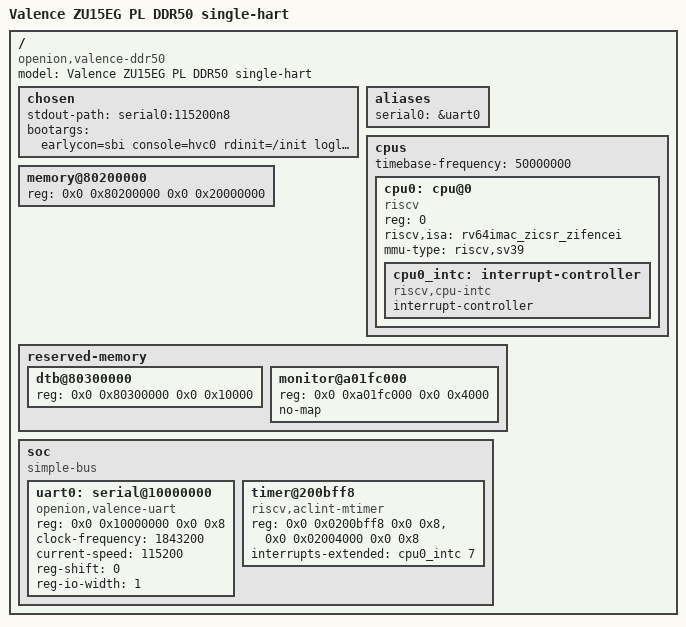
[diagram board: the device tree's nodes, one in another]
/dts-v1/;

/ {
    #address-cells = <2>;
    #size-cells = <2>;
    compatible = "openion,valence-ddr50";
    model = "Valence ZU15EG PL DDR50 single-hart";

    chosen {
        stdout-path = "serial0:115200n8";
        bootargs = "earlycon=sbi console=hvc0 rdinit=/init loglevel=7";
    };
    aliases { serial0 = &uart0; };
    cpus {
        #address-cells = <1>;
        #size-cells = <0>;
        timebase-frequency = <50000000>;
        cpu0: cpu@0 {
            device_type = "cpu";
            reg = <0>;
            compatible = "riscv";
            riscv,isa = "rv64imac_zicsr_zifencei";
            mmu-type = "riscv,sv39";
            status = "okay";
            cpu0_intc: interrupt-controller {
                compatible = "riscv,cpu-intc";
                interrupt-controller;
                #address-cells = <0>;
                #interrupt-cells = <1>;
            };
        };
    };
    memory@80200000 {
        device_type = "memory";
        reg = <0x0 0x80200000 0x0 0x20000000>;
    };
    reserved-memory {
        #address-cells = <2>;
        #size-cells = <2>;
        ranges;
        /* OpenSBI adds its own resident firmware reservation at runtime. */
        dtb@80300000 { reg = <0x0 0x80300000 0x0 0x10000>; };
        monitor@a01fc000 {
            reg = <0x0 0xa01fc000 0x0 0x4000>;
            no-map;
        };
    };
    soc {
        compatible = "simple-bus";
        #address-cells = <2>;
        #size-cells = <2>;
        ranges;
        /* No standard CPU-writable IMSIC aperture: do NOT describe AIA here.
         * Linux uses SBI DBCN/hvc polling. UART IRQ3 is not used in this image. */
        uart0: serial@10000000 {
            compatible = "openion,valence-uart", "ns16550a";
            reg = <0x0 0x10000000 0x0 0x8>;
            clock-frequency = <1843200>;
            current-speed = <115200>;
            reg-shift = <0>;
            reg-io-width = <1>;
            status = "okay";
        };
        timer@200bff8 {
            compatible = "riscv,aclint-mtimer";
            reg = <0x0 0x0200bff8 0x0 0x8>, <0x0 0x02004000 0x0 0x8>;
            interrupts-extended = <&cpu0_intc 7>;
        };
    };
};
